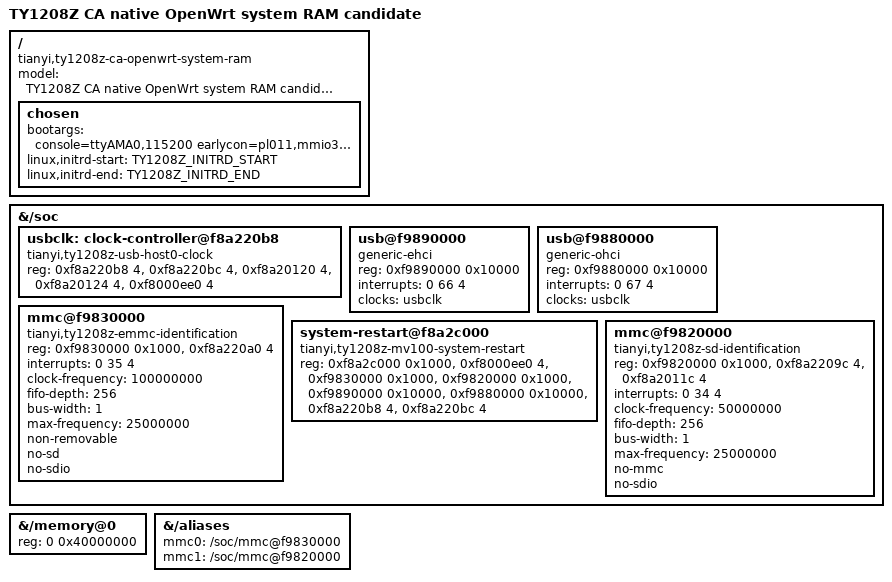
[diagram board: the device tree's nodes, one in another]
// SPDX-License-Identifier: GPL-2.0-only
#define TY1208Z_FULL_MEMORY 1
#include "hi3798mv100-ty1208z-openwrt-smp.dts"

/ {
	model = "TY1208Z CA native OpenWrt system RAM candidate";
	compatible = "tianyi,ty1208z-ca-openwrt-system-ram", "hi3798mv100-series";
	chosen {
		bootargs = "console=ttyAMA0,115200 earlycon=pl011,mmio32,0xf8b00000 rdinit=/init loglevel=7 panic=0 blkdevparts=mmcblk0:1M(boot)ro,1M(bootargs)ro,4M(baseparam)ro,4M(pqparam)ro,4M(logo)ro,20M(kernel)ro,64M(busybox)ro,512M(backup)ro,6846M(ubuntu)ro";
		linux,initrd-start = <TY1208Z_INITRD_START>;
		linux,initrd-end = <TY1208Z_INITRD_END>;
	};
};

&{/soc} {
	usbclk: clock-controller@f8a220b8 {
		compatible = "tianyi,ty1208z-usb-host0-clock";
		reg = <0xf8a220b8 4>, <0xf8a220bc 4>,
		      <0xf8a20120 4>, <0xf8a20124 4>, <0xf8000ee0 4>;
		#clock-cells = <0>;
	};
	usb@f9890000 {
		compatible = "generic-ehci";
		reg = <0xf9890000 0x10000>;
		interrupts = <0 66 4>;
		clocks = <&usbclk>;
	};
	usb@f9880000 {
		compatible = "generic-ohci";
		reg = <0xf9880000 0x10000>;
		interrupts = <0 67 4>;
		clocks = <&usbclk>;
	};
	mmc@f9830000 {
		compatible = "tianyi,ty1208z-emmc-identification";
		reg = <0xf9830000 0x1000>, <0xf8a220a0 4>;
		reg-names = "controller", "crg40";
		interrupts = <0 35 4>;
		clock-frequency = <100000000>;
		fifo-depth = <256>;
		bus-width = <1>;
		max-frequency = <25000000>;
		non-removable;
		no-sd;
		no-sdio;
	};
	system-restart@f8a2c000 {
		compatible = "tianyi,ty1208z-mv100-system-restart";
		reg = <0xf8a2c000 0x1000>, <0xf8000ee0 4>,
		      <0xf9830000 0x1000>, <0xf9820000 0x1000>,
		      <0xf9890000 0x10000>, <0xf9880000 0x10000>,
		      <0xf8a220b8 4>, <0xf8a220bc 4>;
	};
};

&{/memory@0} { reg = <0 0x40000000>; };
&{/aliases} {
	mmc0 = "/soc/mmc@f9830000";
	mmc1 = "/soc/mmc@f9820000";
};
&{/soc} {
	mmc@f9820000 {
		compatible = "tianyi,ty1208z-sd-identification";
		reg = <0xf9820000 0x1000>, <0xf8a2209c 4>, <0xf8a2011c 4>;
		reg-names = "controller", "crg39", "ldo";
		interrupts = <0 34 4>;
		clock-frequency = <50000000>;
		fifo-depth = <256>;
		bus-width = <1>;
		max-frequency = <25000000>;
		no-mmc;
		no-sdio;
	};
};

